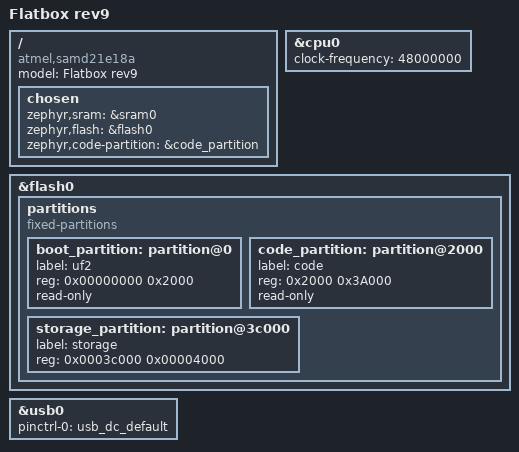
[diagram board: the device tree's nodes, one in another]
/dts-v1/;
#include <atmel/samd21.dtsi>
#include <atmel/samx2xx18.dtsi>
#include "flatbox_rev9-pinctrl.dtsi"

/ {
	model = "Flatbox rev9";
	compatible = "atmel,samd21e18a", "atmel,samd21";

	chosen {
		zephyr,sram = &sram0;
		zephyr,flash = &flash0;
		zephyr,code-partition = &code_partition;
	};

};

&cpu0 {
	clock-frequency = <48000000>;
};

&flash0 {
	partitions {
		compatible = "fixed-partitions";
		#address-cells = <1>;
		#size-cells = <1>;

		boot_partition: partition@0 {
			label = "uf2";
			reg = <0x00000000 0x2000>;
			read-only;
		};

		code_partition: partition@2000 {
			label = "code";
			reg = <0x2000 0x3A000>;
			read-only;
		};

		/*
		 * The final 16 KiB is reserved for the application.
		 * Storage partition will be used by FCB/LittleFS/NVS
		 * if enabled.
		 */
		storage_partition: partition@3c000 {
			label = "storage";
			reg = <0x0003c000 0x00004000>;
		};
	};
};

zephyr_udc0: &usb0 {
	status = "okay";

	pinctrl-0 = <&usb_dc_default>;
	pinctrl-names = "default";
};
